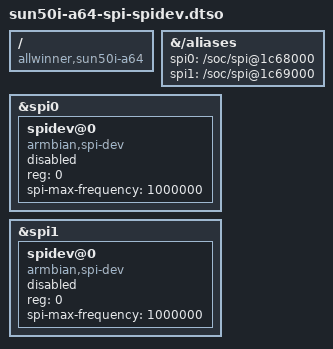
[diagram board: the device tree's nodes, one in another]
/dts-v1/;
/plugin/;

/ {
	compatible = "allwinner,sun50i-a64";

	fragment@0 {
		target-path = "/aliases";
		__overlay__ {
			spi0 = "/soc/spi@1c68000";
			spi1 = "/soc/spi@1c69000";
		};
	};

	fragment@1 {
		target = <&spi0>;
		__overlay__ {
			#address-cells = <1>;
			#size-cells = <0>;
			spidev@0 {
				compatible = "armbian,spi-dev";
				status = "disabled";
				reg = <0>;
				spi-max-frequency = <1000000>;
			};
		};
	};

	fragment@2 {
		target = <&spi1>;
		__overlay__ {
			#address-cells = <1>;
			#size-cells = <0>;
			spidev@0 {
				compatible = "armbian,spi-dev";
				status = "disabled";
				reg = <0>;
				spi-max-frequency = <1000000>;
			};
		};
	};
};
